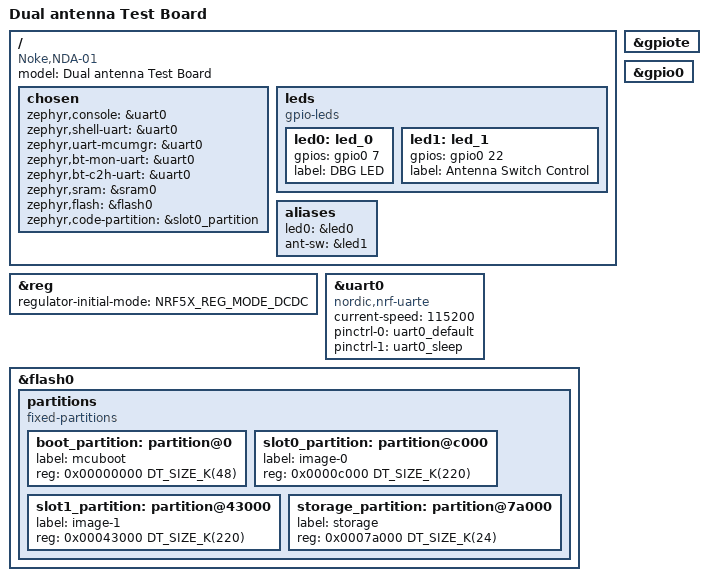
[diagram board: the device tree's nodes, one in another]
/dts-v1/;
#include <nordic/nrf52832_qfaa.dtsi>
#include "NDA_01-pinctrl.dtsi"

/ {
	model = "Dual antenna Test Board";
	compatible = "Noke,NDA-01";

	chosen {
		zephyr,console = &uart0;
		zephyr,shell-uart = &uart0;
		zephyr,uart-mcumgr = &uart0;
		zephyr,bt-mon-uart = &uart0;
		zephyr,bt-c2h-uart = &uart0;
		zephyr,sram = &sram0;
		zephyr,flash = &flash0;
		zephyr,code-partition = &slot0_partition;
	};

	leds {
		compatible = "gpio-leds";
		led0: led_0 {
			gpios = <&gpio0 7 GPIO_ACTIVE_HIGH>;
			label = "DBG LED";
		};
		led1: led_1 {
			gpios = <&gpio0 22 GPIO_ACTIVE_HIGH>;
			label = "Antenna Switch Control";
		};
	};

	aliases {
		led0 = &led0;
		ant-sw = &led1;
	};

};

&reg {
	regulator-initial-mode = <NRF5X_REG_MODE_DCDC>;
};

&gpiote {
	status = "okay";
};

&gpio0 {
	status = "okay";
};

&uart0 {
	status = "okay";
	compatible = "nordic,nrf-uarte";
	current-speed = <115200>;
	pinctrl-0 = <&uart0_default>;
	pinctrl-1 = <&uart0_sleep>;
	pinctrl-names = "default","sleep";
};

&flash0 {
	partitions {
		compatible = "fixed-partitions";
		#address-cells = <1>;
		#size-cells = <1>;

		boot_partition: partition@0 {
			label = "mcuboot";
			reg = <0x00000000 DT_SIZE_K(48)>;
		};

		slot0_partition: partition@c000 {
			label = "image-0";
			reg = <0x0000c000 DT_SIZE_K(220)>;
		};

		slot1_partition: partition@43000 {
			label = "image-1";
			reg = <0x00043000 DT_SIZE_K(220)>;
		};

		storage_partition: partition@7a000 {
			label = "storage";
			reg = <0x0007a000 DT_SIZE_K(24)>;
		};
	};
};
